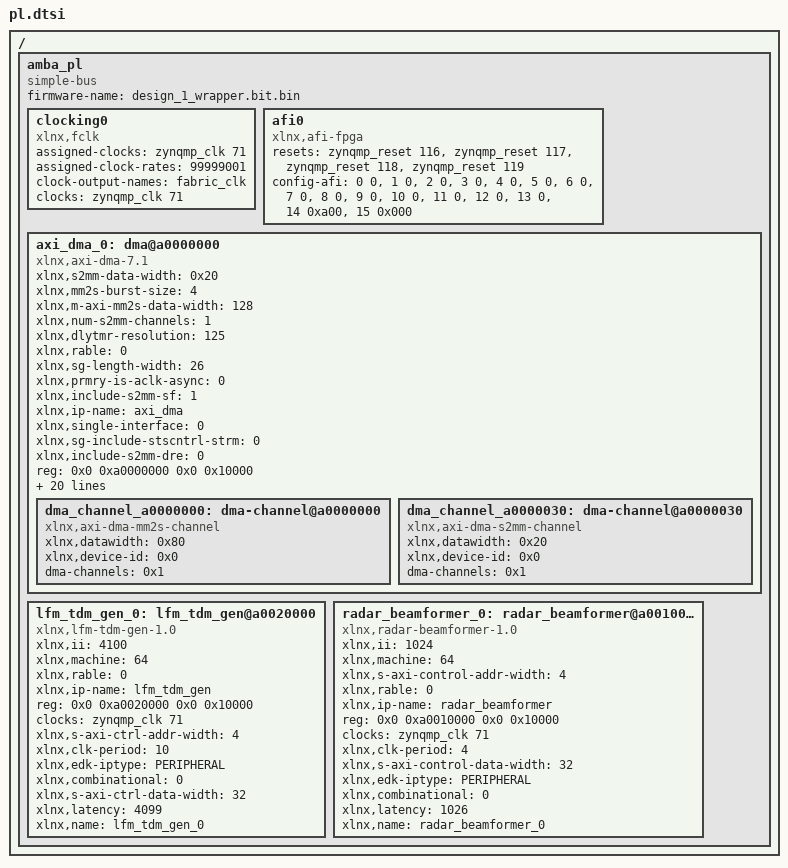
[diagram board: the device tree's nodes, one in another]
/ {
	amba_pl: amba_pl {
		ranges;
		compatible = "simple-bus";
		#address-cells = <2>;
		#size-cells = <2>;
		firmware-name = "design_1_wrapper.bit.bin";
		clocking0: clocking0 {
			compatible = "xlnx,fclk";
			status = "okay";
			assigned-clocks = <&zynqmp_clk 71>;
			assigned-clock-rates = <99999001>;
			#clock-cells = <0>;
			clock-output-names = "fabric_clk";
			clocks = <&zynqmp_clk 71>;
		};
		afi0: afi0 {
			status = "okay";
			compatible = "xlnx,afi-fpga";
			resets = <&zynqmp_reset 116>, <&zynqmp_reset 117>, <&zynqmp_reset 118>, <&zynqmp_reset 119>;
			config-afi = < 0 0>, <1 0>, <2 0>, <3 0>, <4 0>, <5 0>, <6 0>, <7 0>, <8 0>, <9 0>, <10 0>, <11 0>, <12 0>, <13 0>, <14 0xa00>, <15 0x000>;
		};
		axi_dma_0: dma@a0000000 {
			compatible = "xlnx,axi-dma-7.1" , "xlnx,axi-dma-1.00.a";
			xlnx,s2mm-data-width = <0x20>;
			xlnx,mm2s-burst-size = <4>;
			xlnx,m-axi-mm2s-data-width = <128>;
			xlnx,num-s2mm-channels = <1>;
			xlnx,dlytmr-resolution = <125>;
			xlnx,rable = <0>;
			xlnx,sg-length-width = <26>;
			xlnx,prmry-is-aclk-async = <0>;
			xlnx,include-s2mm-sf = <1>;
			#dma-cells = <1>;
			xlnx,ip-name = "axi_dma";
			xlnx,single-interface = <0>;
			xlnx,sg-include-stscntrl-strm = <0>;
			xlnx,include-s2mm-dre = <0>;
			reg = <0x0 0xa0000000 0x0 0x10000>;
			xlnx,addr-width = <32>;
			xlnx,include-s2mm = <1>;
			clocks = <&zynqmp_clk 71>, <&zynqmp_clk 71>, <&zynqmp_clk 71>;
			xlnx,s-axis-s2mm-tdata-width = <32>;
			xlnx,micro-dma = <0>;
			xlnx,increase-throughput = <0>;
			xlnx,mm2s-data-width = <0x80>;
			xlnx,addrwidth = <0x20>;
			xlnx,sg-use-stsapp-length = <0>;
			xlnx,m-axis-mm2s-tdata-width = <128>;
			xlnx,edk-iptype = "PERIPHERAL";
			xlnx,s2mm-burst-size = <16>;
			xlnx,m-axi-s2mm-data-width = <32>;
			xlnx,num-mm2s-channels = <1>;
			xlnx,enable-multi-channel = <0>;
			status = "okay";
			xlnx,include-mm2s-sf = <1>;
			clock-names = "m_axi_mm2s_aclk" , "m_axi_s2mm_aclk" , "s_axi_lite_aclk";
			xlnx,include-mm2s = <1>;
			xlnx,include-mm2s-dre = <0>;
			xlnx,name = "axi_dma_0";
			dma_channel_a0000000: dma-channel@a0000000 {
				xlnx,datawidth = <0x80>;
				xlnx,device-id = <0x0>;
				compatible = "xlnx,axi-dma-mm2s-channel";
				dma-channels = <0x1>;
			};
			dma_channel_a0000030: dma-channel@a0000030 {
				xlnx,datawidth = <0x20>;
				xlnx,device-id = <0x0>;
				compatible = "xlnx,axi-dma-s2mm-channel";
				dma-channels = <0x1>;
			};
		};
		lfm_tdm_gen_0: lfm_tdm_gen@a0020000 {
			compatible = "xlnx,lfm-tdm-gen-1.0";
			xlnx,ii = <4100>;
			xlnx,machine = <64>;
			xlnx,rable = <0>;
			xlnx,ip-name = "lfm_tdm_gen";
			reg = <0x0 0xa0020000 0x0 0x10000>;
			clocks = <&zynqmp_clk 71>;
			xlnx,s-axi-ctrl-addr-width = <4>;
			xlnx,clk-period = <10>;
			xlnx,edk-iptype = "PERIPHERAL";
			status = "okay";
			clock-names = "ap_clk";
			xlnx,combinational = <0>;
			xlnx,s-axi-ctrl-data-width = <32>;
			xlnx,latency = <4099>;
			xlnx,name = "lfm_tdm_gen_0";
		};
		radar_beamformer_0: radar_beamformer@a0010000 {
			compatible = "xlnx,radar-beamformer-1.0";
			xlnx,ii = <1024>;
			xlnx,machine = <64>;
			xlnx,s-axi-control-addr-width = <4>;
			xlnx,rable = <0>;
			xlnx,ip-name = "radar_beamformer";
			reg = <0x0 0xa0010000 0x0 0x10000>;
			clocks = <&zynqmp_clk 71>;
			xlnx,clk-period = <4>;
			xlnx,s-axi-control-data-width = <32>;
			xlnx,edk-iptype = "PERIPHERAL";
			status = "okay";
			clock-names = "ap_clk";
			xlnx,combinational = <0>;
			xlnx,latency = <1026>;
			xlnx,name = "radar_beamformer_0";
		};
	};
};
